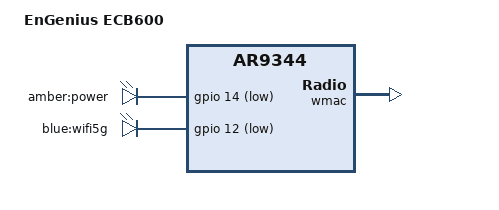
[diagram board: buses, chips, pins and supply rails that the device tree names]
// SPDX-License-Identifier: GPL-2.0-or-later OR MIT

#include "ar9344_engenius_exx600.dtsi"

/ {
	model = "EnGenius ECB600";
	compatible = "engenius,ecb600", "qca,ar9344";

	leds {
		compatible = "gpio-leds";

		led_power: power {
			label = "amber:power";
			gpios = <&gpio 14 GPIO_ACTIVE_LOW>;
			default-state = "on";
		};

		wifi5g {
			label = "blue:wifi5g";
			gpios = <&gpio 12 GPIO_ACTIVE_LOW>;
			linux,default-trigger = "phy0tpt";
		};
	};
};

&eth0 {
	mtd-mac-address = <&art 0x0>;
};

&pcie {
	wifi@0,0,0 {
		mtd-mac-address = <&art 0x0>;
		mtd-mac-address-increment = <(-2)>;
	};
};

&wmac {
	mtd-mac-address = <&art 0x0>;
	mtd-mac-address-increment = <(-1)>;
};
